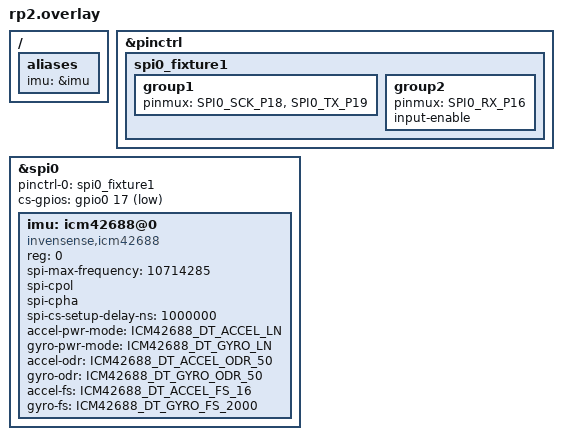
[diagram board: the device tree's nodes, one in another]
/* SPDX-License-Identifier: Apache-2.0 OR MIT */

#include <zephyr/dt-bindings/gpio/gpio.h>
#include <zephyr/dt-bindings/pinctrl/rpi-pico-rp2350a-pinctrl.h>
#include <zephyr/dt-bindings/sensor/icm42688.h>

/ {
	aliases {
		imu = &imu;
	};
};

&pinctrl {
	spi0_fixture1: spi0_fixture1 {
		group1 {
			pinmux = <SPI0_SCK_P18>, <SPI0_TX_P19>;
		};
		group2 {
			pinmux = <SPI0_RX_P16>;
			input-enable;
		};
	};
};

/*
 * A GPIO chip select: the driver splits every register read into a command
 * chunk and a data chunk, and the PL022's own chip select would drop between
 * them. The target latches the command once per chip-select window.
 */
&spi0 {
	status = "okay";
	pinctrl-0 = <&spi0_fixture1>;
	pinctrl-names = "default";
	cs-gpios = <&gpio0 17 GPIO_ACTIVE_LOW>;

	imu: icm42688@0 {
		compatible = "invensense,icm42688", "invensense,icm4268x";
		reg = <0>;
		spi-max-frequency = <10714285>;
		spi-cpol;
		spi-cpha;
		spi-cs-setup-delay-ns = <1000000>;
		/* Low-noise on both, so PWR_MGMT0 gets a real write and the part
		 * raises DATA_RDY; 50 Hz away from the default so the config
		 * registers carry a value the model has to store and hand back. */
		accel-pwr-mode = <ICM42688_DT_ACCEL_LN>;
		gyro-pwr-mode = <ICM42688_DT_GYRO_LN>;
		accel-odr = <ICM42688_DT_ACCEL_ODR_50>;
		gyro-odr = <ICM42688_DT_GYRO_ODR_50>;
		accel-fs = <ICM42688_DT_ACCEL_FS_16>;
		gyro-fs = <ICM42688_DT_GYRO_FS_2000>;
		status = "okay";
	};
};
